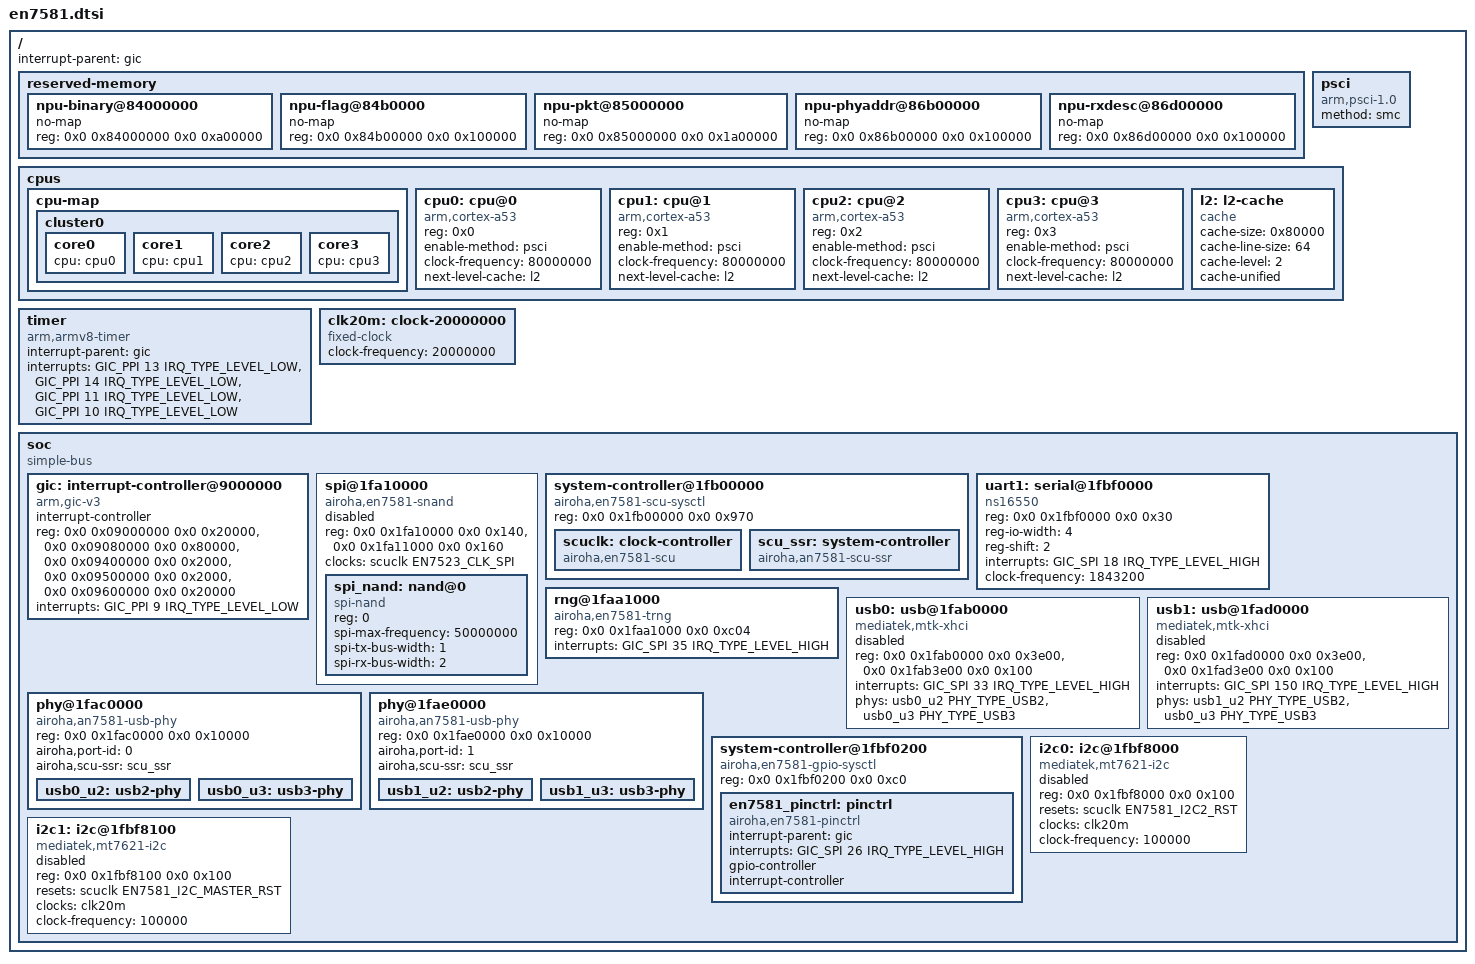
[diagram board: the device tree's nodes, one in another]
// SPDX-License-Identifier: (GPL-2.0-only OR BSD-2-Clause)

#include <dt-bindings/interrupt-controller/irq.h>
#include <dt-bindings/interrupt-controller/arm-gic.h>
#include <dt-bindings/clock/en7523-clk.h>
#include <dt-bindings/phy/phy.h>
#include <dt-bindings/reset/airoha,en7581-reset.h>

/ {
	interrupt-parent = <&gic>;
	#address-cells = <2>;
	#size-cells = <2>;

	reserved-memory {
		#address-cells = <2>;
		#size-cells = <2>;
		ranges;

		npu-binary@84000000 {
			no-map;
			reg = <0x0 0x84000000 0x0 0xa00000>;
		};

		npu-flag@84b0000 {
			no-map;
			reg = <0x0 0x84b00000 0x0 0x100000>;
		};

		npu-pkt@85000000 {
			no-map;
			reg = <0x0 0x85000000 0x0 0x1a00000>;
		};

		npu-phyaddr@86b00000 {
			no-map;
			reg = <0x0 0x86b00000 0x0 0x100000>;
		};

		npu-rxdesc@86d00000 {
			no-map;
			reg = <0x0 0x86d00000 0x0 0x100000>;
		};
	};

	psci {
		compatible = "arm,psci-1.0";
		method = "smc";
	};

	cpus {
		#address-cells = <1>;
		#size-cells = <0>;

		cpu-map {
			cluster0 {
				core0 {
					cpu = <&cpu0>;
				};

				core1 {
					cpu = <&cpu1>;
				};

				core2 {
					cpu = <&cpu2>;
				};

				core3 {
					cpu = <&cpu3>;
				};
			};
		};

		cpu0: cpu@0 {
			device_type = "cpu";
			compatible = "arm,cortex-a53";
			reg = <0x0>;
			enable-method = "psci";
			clock-frequency = <80000000>;
			next-level-cache = <&l2>;
		};

		cpu1: cpu@1 {
			device_type = "cpu";
			compatible = "arm,cortex-a53";
			reg = <0x1>;
			enable-method = "psci";
			clock-frequency = <80000000>;
			next-level-cache = <&l2>;
		};

		cpu2: cpu@2 {
			device_type = "cpu";
			compatible = "arm,cortex-a53";
			reg = <0x2>;
			enable-method = "psci";
			clock-frequency = <80000000>;
			next-level-cache = <&l2>;
		};

		cpu3: cpu@3 {
			device_type = "cpu";
			compatible = "arm,cortex-a53";
			reg = <0x3>;
			enable-method = "psci";
			clock-frequency = <80000000>;
			next-level-cache = <&l2>;
		};

		l2: l2-cache {
			compatible = "cache";
			cache-size = <0x80000>;
			cache-line-size = <64>;
			cache-level = <2>;
			cache-unified;
		};
	};

	timer {
		compatible = "arm,armv8-timer";
		interrupt-parent = <&gic>;
		interrupts = <GIC_PPI 13 IRQ_TYPE_LEVEL_LOW>,
			     <GIC_PPI 14 IRQ_TYPE_LEVEL_LOW>,
			     <GIC_PPI 11 IRQ_TYPE_LEVEL_LOW>,
			     <GIC_PPI 10 IRQ_TYPE_LEVEL_LOW>;
	};

	clk20m: clock-20000000 {
		compatible = "fixed-clock";
		#clock-cells = <0>;
		clock-frequency = <20000000>;
	};

	soc {
		compatible = "simple-bus";
		#address-cells = <2>;
		#size-cells = <2>;
		ranges;

		gic: interrupt-controller@9000000 {
			compatible = "arm,gic-v3";
			interrupt-controller;
			#interrupt-cells = <3>;
			#address-cells = <1>;
			#size-cells = <1>;
			reg = <0x0 0x09000000 0x0 0x20000>,
			      <0x0 0x09080000 0x0 0x80000>,
			      <0x0 0x09400000 0x0 0x2000>,
			      <0x0 0x09500000 0x0 0x2000>,
			      <0x0 0x09600000 0x0 0x20000>;
			interrupts = <GIC_PPI 9 IRQ_TYPE_LEVEL_LOW>;
		};

		spi@1fa10000 {
			compatible = "airoha,en7581-snand";
			reg = <0x0 0x1fa10000 0x0 0x140>,
			      <0x0 0x1fa11000 0x0 0x160>;

			clocks = <&scuclk EN7523_CLK_SPI>;
			clock-names = "spi";

			#address-cells = <1>;
			#size-cells = <0>;

			status = "disabled";

			spi_nand: nand@0 {
				compatible = "spi-nand";
				reg = <0>;

				spi-max-frequency = <50000000>;
				spi-tx-bus-width = <1>;
				spi-rx-bus-width = <2>;
			};
		};

		system-controller@1fb00000 {
			compatible = "airoha,en7581-scu-sysctl", "syscon", "simple-mfd";
			reg = <0x0 0x1fb00000 0x0 0x970>;

			scuclk: clock-controller {
				compatible = "airoha,en7581-scu";

				#clock-cells = <1>;
				#reset-cells = <1>;
			};

			scu_ssr: system-controller {
				compatible = "airoha,an7581-scu-ssr";
			};
		};

		uart1: serial@1fbf0000 {
			compatible = "ns16550";
			reg = <0x0 0x1fbf0000 0x0 0x30>;
			reg-io-width = <4>;
			reg-shift = <2>;
			interrupts = <GIC_SPI 18 IRQ_TYPE_LEVEL_HIGH>;
			clock-frequency = <1843200>;
		};

		rng@1faa1000 {
			compatible = "airoha,en7581-trng";
			reg = <0x0 0x1faa1000 0x0 0xc04>;
			interrupts = <GIC_SPI 35 IRQ_TYPE_LEVEL_HIGH>;
		};

		usb0: usb@1fab0000 {
			compatible = "mediatek,mtk-xhci";
			reg = <0x0 0x1fab0000 0x0 0x3e00>,
				<0x0 0x1fab3e00 0x0 0x100>;
			reg-names = "mac", "ippc";
			interrupts = <GIC_SPI 33 IRQ_TYPE_LEVEL_HIGH>;

			phys = <&usb0_u2 PHY_TYPE_USB2>, <&usb0_u3 PHY_TYPE_USB3>;

			status = "disabled";
		};

		phy@1fac0000 {
			compatible = "airoha,an7581-usb-phy";
			reg = <0x0 0x1fac0000 0x0 0x10000>;

			airoha,port-id = <0>;
			airoha,scu-ssr = <&scu_ssr>;

			usb0_u2: usb2-phy {
				#phy-cells = <1>;
			};

			usb0_u3: usb3-phy {
				#phy-cells = <1>;
			};
		};

		usb1: usb@1fad0000 {
			compatible = "mediatek,mtk-xhci";
			reg = <0x0 0x1fad0000 0x0 0x3e00>,
				<0x0 0x1fad3e00 0x0 0x100>;
			reg-names = "mac", "ippc";
			interrupts = <GIC_SPI 150 IRQ_TYPE_LEVEL_HIGH>;

			phys = <&usb1_u2 PHY_TYPE_USB2>, <&usb0_u3 PHY_TYPE_USB3>;

			status = "disabled";
		};

		phy@1fae0000 {
			compatible = "airoha,an7581-usb-phy";
			reg = <0x0 0x1fae0000 0x0 0x10000>;

			airoha,port-id = <1>;
			airoha,scu-ssr = <&scu_ssr>;

			usb1_u2: usb2-phy {
				#phy-cells = <1>;
			};

			usb1_u3: usb3-phy {
				#phy-cells = <1>;
			};
		};

		system-controller@1fbf0200 {
			compatible = "airoha,en7581-gpio-sysctl", "syscon",
				     "simple-mfd";
			reg = <0x0 0x1fbf0200 0x0 0xc0>;

			en7581_pinctrl: pinctrl {
				compatible = "airoha,en7581-pinctrl";

				interrupt-parent = <&gic>;
				interrupts = <GIC_SPI 26 IRQ_TYPE_LEVEL_HIGH>;

				gpio-controller;
				#gpio-cells = <2>;

				interrupt-controller;
				#interrupt-cells = <2>;
			};
		};

		i2c0: i2c@1fbf8000 {
			compatible = "mediatek,mt7621-i2c";
			reg = <0x0 0x1fbf8000 0x0 0x100>;

			resets = <&scuclk EN7581_I2C2_RST>;

			clocks = <&clk20m>;
			clock-frequency = <100000>;
			#address-cells = <1>;
			#size-cells = <0>;

			status = "disabled";
		};

		i2c1: i2c@1fbf8100 {
			compatible = "mediatek,mt7621-i2c";
			reg = <0x0 0x1fbf8100 0x0 0x100>;

			resets = <&scuclk EN7581_I2C_MASTER_RST>;

			clocks = <&clk20m>;
			clock-frequency = <100000>;
			#address-cells = <1>;
			#size-cells = <0>;

			status = "disabled";
		};
	};
};
